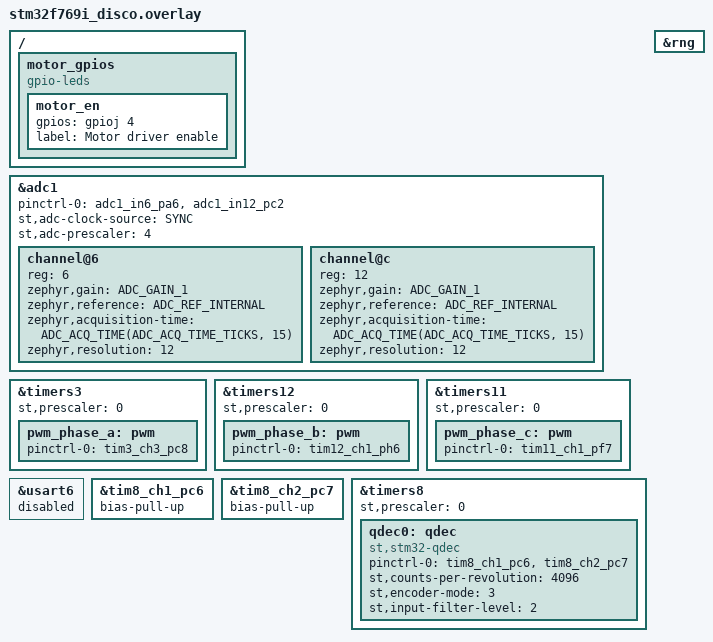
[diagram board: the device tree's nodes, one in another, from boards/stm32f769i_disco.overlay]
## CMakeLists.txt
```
cmake_minimum_required(VERSION 3.20.0)

find_package(Zephyr REQUIRED HINTS $ENV{ZEPHYR_BASE})
project(bldc_foc_control VERSION 1.0.0)

target_sources(app PRIVATE
    src/main.c
    src/foc/pid.c
    src/foc/foc.c
    src/motor/motor.c
    src/interface/cmd.c
)

if(CONFIG_MOTOR_SIM)
    target_sources(app PRIVATE src/sim/sim.c)
endif()

target_include_directories(app PRIVATE src)
```

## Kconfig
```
config MOTOR_SIM
	bool "Motor simulation mode"
	default n
	help
	  Replace ADC current sensing and encoder feedback with a simulated
	  surface-mounted PMSM (SPMSM) motor model. PWM outputs remain active
	  so duty cycles can be verified with an oscilloscope.

	  Motor model parameters (src/sim/sim.h):
	    R    = 0.5  Ω       stator resistance
	    L    = 1 mH         stator inductance (Ld = Lq)
	    psi  = 0.05 Wb      permanent-magnet flux linkage
	    J    = 1e-5 kg·m²   moment of inertia
	    B    = 1e-4 N·m·s   viscous friction

	  Enable in prj.conf with CONFIG_MOTOR_SIM=y.

# Pull in Zephyr's full Kconfig tree (required when this file is used as root).
source "Kconfig.zephyr"
```

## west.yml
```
manifest:
  remotes:
    - name: zephyrproject-rtos
      url-base: https://github.com/zephyrproject-rtos

  projects:
    - name: zephyr
      remote: zephyrproject-rtos
      revision: v3.7.0
      import: true

  self:
    path: app
```

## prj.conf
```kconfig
# ─── Simulation mode ─────────────────────────────────────────────────────────
# Uncomment to replace ADC/encoder with a synthetic SPMSM motor model.
# PWM outputs remain active — use an oscilloscope to verify duty cycles.
# CONFIG_MOTOR_SIM=y

# ─── Core ────────────────────────────────────────────────────────────────────
CONFIG_FPU=y
CONFIG_FPU_SHARING=y
CONFIG_MAIN_STACK_SIZE=4096
CONFIG_SYSTEM_WORKQUEUE_STACK_SIZE=4096
CONFIG_HEAP_MEM_POOL_SIZE=32768

# Higher tick rate for 10 kHz control loop (100 µs resolution)
CONFIG_SYS_CLOCK_TICKS_PER_SEC=10000

# ─── Drivers ─────────────────────────────────────────────────────────────────
CONFIG_GPIO=y
CONFIG_ADC=y
CONFIG_PWM=y
CONFIG_SENSOR=y
CONFIG_QDEC_STM32=y
CONFIG_REBOOT=y

# ─── Math / printf with float support ────────────────────────────────────────
CONFIG_CBPRINTF_FP_SUPPORT=y

# ─── Logging ─────────────────────────────────────────────────────────────────
CONFIG_LOG=y
CONFIG_LOG_DEFAULT_LEVEL=3

# ─── Shell over USART1 (ST-Link VCP, 115200 baud) ────────────────────────────
CONFIG_SHELL=y
CONFIG_SHELL_BACKEND_SERIAL=y
CONFIG_SHELL_STACK_SIZE=4096
CONFIG_UART_CONSOLE=y

# ─── Entropy (required by networking stack for sys_rand_get) ─────────────────
CONFIG_ENTROPY_GENERATOR=y
CONFIG_ENTROPY_STM32_RNG=y

# ─── Networking (Ethernet UDP interface) ─────────────────────────────────────
CONFIG_NETWORKING=y
CONFIG_NET_IPV4=y
CONFIG_NET_UDP=y
CONFIG_NET_SOCKETS=y
CONFIG_NET_L2_ETHERNET=y
CONFIG_NET_ARP=y
CONFIG_NET_CONFIG_SETTINGS=y
CONFIG_NET_CONFIG_AUTO_INIT=y
CONFIG_NET_CONFIG_INIT_TIMEOUT=30
CONFIG_NET_CONFIG_MY_IPV4_ADDR="192.168.7.100"
CONFIG_NET_CONFIG_MY_IPV4_NETMASK="255.255.255.0"
CONFIG_NET_CONFIG_MY_IPV4_GW="192.168.7.1"
CONFIG_NET_CONFIG_NEED_IPV4=y
CONFIG_ETH_STM32_HAL=y
CONFIG_NET_PKT_RX_COUNT=8
CONFIG_NET_PKT_TX_COUNT=8
CONFIG_NET_BUF_RX_COUNT=16
CONFIG_NET_BUF_TX_COUNT=16
```

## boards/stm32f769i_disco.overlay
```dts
/*
 * Board overlay — BLDC FOC motor control shield
 *
 * Pin mapping:
 *   PA6  → ADC1 CH6  — Phase A current sense
 *   PC2  → ADC1 CH12 — Phase B current sense
 *   PC8  → TIM3 CH3  — Phase A PWM
 *   PH6  → TIM12 CH1 — Phase B PWM
 *   PF7  → TIM11 CH1 — Phase C PWM
 *   PC6  → TIM8 CH1  — Encoder signal A (Arduino D1)
 *   PC7  → TIM8 CH2  — Encoder signal B (Arduino D0)
 *   PJ4  → GPIO OUT  — Motor driver enable (active-high)
 *
 * NOTE: Verify pinctrl node names against your Zephyr version's
 * dts/arm/st/f7/stm32f769ig-pinctrl.dtsi before building.
 */

/* ─── Current sensing ────────────────────────────────────────────────────── */
&adc1 {
	pinctrl-0 = <&adc1_in6_pa6 &adc1_in12_pc2>;
	pinctrl-names = "default";
	st,adc-clock-source = "SYNC";
	st,adc-prescaler = <4>;
	#address-cells = <1>;
	#size-cells = <0>;
	status = "okay";

	/* Phase A — PA6 */
	channel@6 {
		reg = <6>;
		zephyr,gain = "ADC_GAIN_1";
		zephyr,reference = "ADC_REF_INTERNAL";
		zephyr,acquisition-time = <ADC_ACQ_TIME(ADC_ACQ_TIME_TICKS, 15)>;
		zephyr,resolution = <12>;
	};

	/* Phase B — PC2 */
	channel@c {
		reg = <12>;
		zephyr,gain = "ADC_GAIN_1";
		zephyr,reference = "ADC_REF_INTERNAL";
		zephyr,acquisition-time = <ADC_ACQ_TIME(ADC_ACQ_TIME_TICKS, 15)>;
		zephyr,resolution = <12>;
	};
};

/* ─── Phase A PWM — PC8 / TIM3 CH3 ─────────────────────────────────────── */
&timers3 {
	status = "okay";
	st,prescaler = <0>;

	pwm_phase_a: pwm {
		status = "okay";
		pinctrl-0 = <&tim3_ch3_pc8>;
		pinctrl-names = "default";
	};
};

/* ─── Phase B PWM — PH6 / TIM12 CH1 ────────────────────────────────────── */
&timers12 {
	status = "okay";
	st,prescaler = <0>;

	pwm_phase_b: pwm {
		status = "okay";
		pinctrl-0 = <&tim12_ch1_ph6>;
		pinctrl-names = "default";
	};
};

/* ─── Phase C PWM — PF7 / TIM11 CH1 ────────────────────────────────────── */
&timers11 {
	status = "okay";
	st,prescaler = <0>;

	pwm_phase_c: pwm {
		status = "okay";
		pinctrl-0 = <&tim11_ch1_pf7>;
		pinctrl-names = "default";
	};
};

/* ─── Motor enable GPIO ─────────────────────────────────────────────────── */
/ {
	motor_gpios {
		compatible = "gpio-leds";  /* Reuse binding; we just need GPIO nodes */

		motor_en: motor_en {
			gpios = <&gpioj 4 GPIO_ACTIVE_HIGH>;
			label = "Motor driver enable";
		};
	};
};

/* PC6/PC7 are the Arduino D1/D0 serial pins (USART6 in the board DTS).
 * Disable USART6 so it does not reconfigure the pins away from TIM8 AF. */
&usart6 {
	status = "disabled";
};

/* ─── TIM8 hardware encoder interface — PC6 (D1) / PC7 (D0) ─────────────── */

/* Pull-ups required for open-collector encoder outputs. */
&tim8_ch1_pc6 {
	bias-pull-up;
};
&tim8_ch2_pc7 {
	bias-pull-up;
};

&timers8 {
	status = "okay";
	st,prescaler = <0>;

	qdec0: qdec {
		compatible = "st,stm32-qdec";
		pinctrl-0 = <&tim8_ch1_pc6 &tim8_ch2_pc7>;
		pinctrl-names = "default";
		st,counts-per-revolution = <4096>;
		st,encoder-mode = <3>;         /* X4_TI12: count all edges on both channels */
		st,input-filter-level = <2>;   /* Fs=F_clk, N=4 → rejects glitches < 4 cycles */
		status = "okay";
	};
};

/* Shell runs over USART1 (already the board's chosen zephyr,shell-uart).
 * Connect via the ST-Link VCP at 115200 baud. */

/* ─── Hardware RNG (required by networking stack) ────────────────────────── */
&rng {
	status = "okay";
};

/* Ethernet is fully configured in the board's base DTS (stm32f769i_disco.dts).
 * No overlay needed — the LAN8742A PHY node and pinctrl are already there. */
```

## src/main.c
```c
#include <zephyr/kernel.h>
#include <zephyr/logging/log.h>

#include "foc/foc.h"
#include "motor/motor.h"
#include "interface/cmd.h"

LOG_MODULE_REGISTER(main, LOG_LEVEL_INF);

/* ─── Thread definitions ─────────────────────────────────────────────────── */

#define FOC_THREAD_STACK  2048
#define UDP_THREAD_STACK  4096
#define FOC_THREAD_PRIO   (1)    /* Preemptive, high priority — blocks on k_sem_take,
                                  * yielding to shell/UDP (priority 5) between steps */
#define UDP_THREAD_PRIO     5

K_THREAD_STACK_DEFINE(foc_stack, FOC_THREAD_STACK);
K_THREAD_STACK_DEFINE(udp_stack, UDP_THREAD_STACK);

static struct k_thread foc_thread;
static struct k_thread udp_thread;

/* ─── FOC control loop ───────────────────────────────────────────────────── */

/*
 * Timer fires at FOC_CONTROL_HZ, posts semaphore to wake control thread.
 * This avoids busy-waiting while still giving precise timing.
 */
static K_SEM_DEFINE(foc_sem, 0, 1);
static struct k_timer foc_timer;

static void foc_timer_cb(struct k_timer *t)
{
	ARG_UNUSED(t);
	k_sem_give(&foc_sem);
}

static void foc_thread_fn(void *p1, void *p2, void *p3)
{
	ARG_UNUSED(p1);
	ARG_UNUSED(p2);
	ARG_UNUSED(p3);

	k_timer_init(&foc_timer, foc_timer_cb, NULL);
	k_timer_start(&foc_timer,
	              K_USEC(1000000 / FOC_CONTROL_HZ),
	              K_USEC(1000000 / FOC_CONTROL_HZ));

	LOG_INF("FOC control loop started at %d Hz", FOC_CONTROL_HZ);

	while (1) {
		k_sem_take(&foc_sem, K_FOREVER);

		float ia, ib, theta, omega, pos;

		if (motor_read_currents(&ia, &ib) != 0) {
			/* ADC error — keep running with zero current */
			ia = ib = 0.0f;
		}

		motor_read_encoder(&theta, &omega, &pos);
		foc_step(&g_foc, ia, ib, theta, omega, pos);
		motor_set_pwm(g_foc.da, g_foc.db, g_foc.dc);

#ifdef CONFIG_MOTOR_SIM
		motor_sim_update(g_foc.vd, g_foc.vq, FOC_CONTROL_DT);
#endif
	}
}

/* ─── UDP server thread ──────────────────────────────────────────────────── */

static void udp_thread_fn(void *p1, void *p2, void *p3)
{
	ARG_UNUSED(p1);
	ARG_UNUSED(p2);
	ARG_UNUSED(p3);

	/* Give networking stack time to come up */
	k_sleep(K_SECONDS(2));

	udp_server_run();  /* blocks forever */
}

/* ─── main ───────────────────────────────────────────────────────────────── */

int main(void)
{
	LOG_INF("BLDC FOC Controller — STM32F769I-DISCO");
	LOG_INF("Firmware built " __DATE__ " " __TIME__);

	/* Initialise motor hardware */
	int ret = motor_init();

	if (ret) {
		LOG_ERR("motor_init failed: %d — halting", ret);
		return ret;
	}

	/* Initialise FOC context */
	foc_init(&g_foc, MOTOR_VBUS_V);

	/* USB is initialised automatically by the kernel via the
	 * cdc_acm_uart0 node in the device tree overlay. */

	/* Start control thread */
	k_thread_create(&foc_thread, foc_stack, FOC_THREAD_STACK,
	                foc_thread_fn, NULL, NULL, NULL,
	                FOC_THREAD_PRIO, 0, K_NO_WAIT);
	k_thread_name_set(&foc_thread, "foc_ctrl");

	/* Start UDP server thread */
	k_thread_create(&udp_thread, udp_stack, UDP_THREAD_STACK,
	                udp_thread_fn, NULL, NULL, NULL,
	                UDP_THREAD_PRIO, 0, K_NO_WAIT);
	k_thread_name_set(&udp_thread, "udp_srv");

	LOG_INF("Ready — connect via USB serial or UDP %s:%d",
	        CONFIG_NET_CONFIG_MY_IPV4_ADDR, 5000);

	return 0;
}
```
